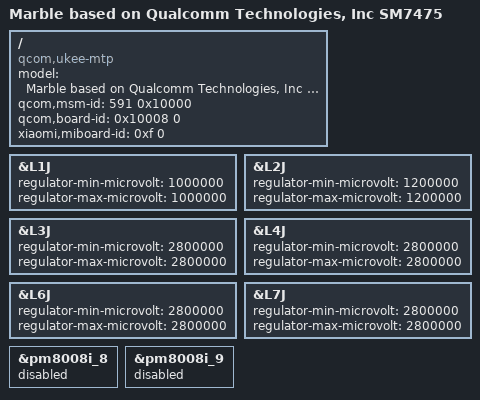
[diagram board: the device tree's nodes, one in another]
/dts-v1/;
/plugin/;

#include <dt-bindings/clock/qcom,camcc-waipio.h>
#include <dt-bindings/clock/qcom,gcc-waipio.h>
#include <dt-bindings/interconnect/qcom,waipio.h>
#include <dt-bindings/interrupt-controller/arm-gic.h>
#include <dt-bindings/regulator/qcom,rpmh-regulator-levels.h>

#include "marble-sm7475.dtsi"
#include "waipio-pm8008.dtsi"
#include "audio/marble-audio.dtsi"
#include "camera/marble-sm7475-camera-sensor.dtsi"
#include "display/display/marble-sde-display-mtp.dtsi"

/ {
	model = "Marble based on Qualcomm Technologies, Inc SM7475";
	compatible = "qcom,ukee-mtp", "qcom,ukee", "qcom,mtp";
	qcom,msm-id = <591 0x10000>;
	qcom,board-id = <0x10008 0>;
	xiaomi,miboard-id = <0xf 0>;
};

&L1J {
	regulator-min-microvolt = <1000000>;
	regulator-max-microvolt = <1000000>;
};

&L2J {
	regulator-min-microvolt = <1200000>;
	regulator-max-microvolt = <1200000>;
};

&L3J {
	regulator-min-microvolt = <2800000>;
	regulator-max-microvolt = <2800000>;
};

&L4J {
	regulator-min-microvolt = <2800000>;
	regulator-max-microvolt = <2800000>;
};

&L6J {
	regulator-min-microvolt = <2800000>;
	regulator-max-microvolt = <2800000>;
};

&L7J {
	regulator-min-microvolt = <2800000>;
	regulator-max-microvolt = <2800000>;
};

/*
 * Marble has no PM8008I: nothing answers at 0x8 (-ENOTCONN) and the stock DT
 * has no consumer for its regulators. Leaving it on keeps pm8008i-regulator
 * deferred, which blocks sync_state of the RPMh regulators it is supplied by.
 */
&pm8008i_8 {
	status = "disabled";
};

&pm8008i_9 {
	status = "disabled";
};
